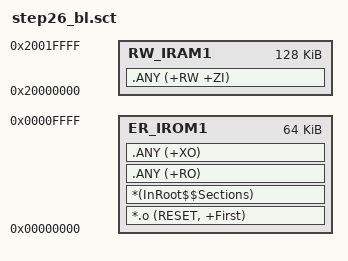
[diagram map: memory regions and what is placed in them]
;===========================================================================
; step26_bl.sct — BootLoader 分散加载文件
;
; BL 固定在第 1 个 64KB: 0x00000000 ~ 0x0000FFFF
; 所有代码和数据必须在此范围内。
;===========================================================================

LR_IROM1 0x00000000 0x00010000  {    ; BL 加载区 (64KB)
  ER_IROM1 0x00000000 0x00010000  {  ; 执行区
    *.o (RESET, +First)             ; 向量表在 0x0
    *(InRoot$$Sections)             ; 根区
    .ANY (+RO)                      ; 所有只读段
    .ANY (+XO)                      ; 只执行段
  }
  RW_IRAM1 0x20000000 0x00020000  {  ; 128KB 内部 SRAM
    .ANY (+RW +ZI)
  }
}
